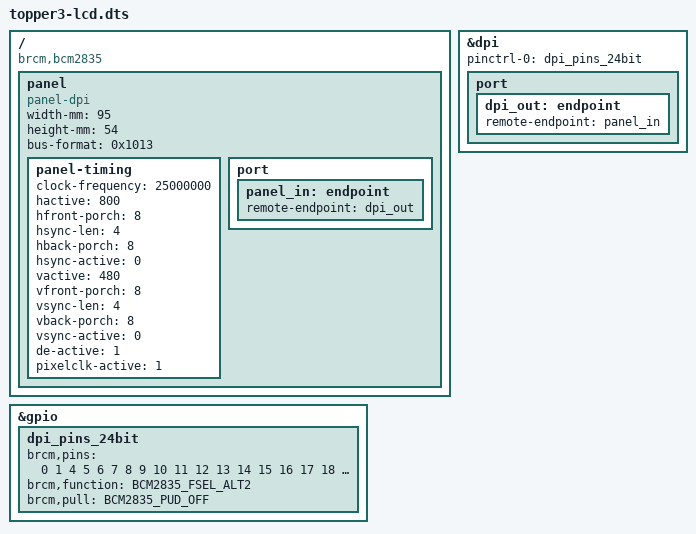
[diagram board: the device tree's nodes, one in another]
/*
 * topper3-lcd-overlay.dts
 *
 * Combined overlay for Compute Module and Pi Zero variants.
 *
 * Default (no params):  24-bit mode (Compute Module pin layout)
 * For Pi Zero:          dtoverlay=topper3-lcd,21bit
 *
 * Note: I2C1 on GPIOs 2/3 is omitted here.
 * Enable it separately with: dtoverlay=i2c1
 */

/dts-v1/;
/plugin/;

#include <dt-bindings/gpio/gpio.h>
#include <dt-bindings/pinctrl/bcm2835.h>

/ {
    compatible = "brcm,bcm2835";

    /* Enable DPI; defaults to 24-bit (Compute Module) pin layout */
    fragment@0 {
        target = <&dpi>;
        __overlay__ {
            status = "okay";
            pinctrl-names = "default";
            pinctrl-0 = <&dpi_pins_24bit>;
        };
    };

    /* 24-bit mode: full 26-pin DPI bus (always active, default) */
    fragment@1 {
        target = <&gpio>;
        __overlay__ {
            dpi_pins_24bit: dpi_pins_24bit {
                brcm,pins = <0 1 4 5 6 7 8 9 10 11 12 13 14 15 16 17 18 19 20 21 22 23 24 25 26 27>;
                brcm,function = <BCM2835_FSEL_ALT2>;
                brcm,pull = <BCM2835_PUD_OFF>;
            };
        };
    };

    /* Pi Zero: define the 21-bit pin group (dormant by default) */
    fragment@2 {
        target = <&gpio>;
        __dormant__ {
            dpi_pins_21bit: dpi_pins_21bit {
                brcm,pins = <0 1 5 6 7 8 9 10 11 13 14 15 16 17 18 19 21 22 23 24 25 26 27>;
                brcm,function = <BCM2835_FSEL_ALT2>;
                brcm,pull = <BCM2835_PUD_OFF>;
            };
        };
    };

    /*
     * Pi Zero: overwrite dpi's pinctrl-0 to point at the 21-bit pin group.
     * Fires after fragment@0 so it wins. Dormant by default.
     */
    fragment@3 {
        target = <&dpi>;
        __dormant__ {
            pinctrl-0 = <&dpi_pins_21bit>;
        };
    };

    fragment@4 {
        target-path = "/";
        __overlay__ {
            panel: panel {
                compatible = "panel-dpi";
                width-mm = <95>;
                height-mm = <54>;
                bus-format = <0x1013>; /* MEDIA_BUS_FMT_BGR888_1X24 */

                panel-timing {
                    clock-frequency = <25000000>;
                    hactive = <800>;
                    hfront-porch = <8>;
                    hsync-len = <4>;
                    hback-porch = <8>;
                    hsync-active = <0>;
                    vactive = <480>;
                    vfront-porch = <8>;
                    vsync-len = <4>;
                    vback-porch = <8>;
                    vsync-active = <0>;
                    de-active = <1>;
                    pixelclk-active = <1>;
                };

                port {
                    panel_in: endpoint {
                        remote-endpoint = <&dpi_out>;
                    };
                };
            };
        };
    };

    fragment@5 {
        target = <&dpi>;
        __overlay__ {
            port {
                dpi_out: endpoint {
                    remote-endpoint = <&panel_in>;
                };
            };
        };
    };

    __overrides__ {
        /* Enable both the 21-bit pin group and the pinctrl-0 override fragment */
        21bit = <0>,"=2",
                <0>,"=3";
    };
};
